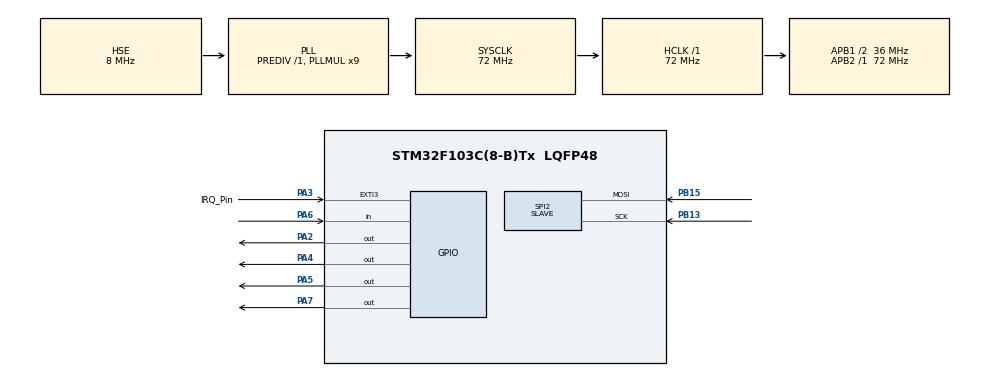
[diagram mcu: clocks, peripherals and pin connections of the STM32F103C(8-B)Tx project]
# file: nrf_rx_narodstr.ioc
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Dma.Request0=SPI2_RX
Dma.SPI2_RX.0.Direction=DMA_PERIPH_TO_MEMORY
Dma.SPI2_RX.0.Instance=DMA1_Channel4
Dma.SPI2_RX.0.MemDataAlignment=DMA_MDATAALIGN_HALFWORD
Dma.SPI2_RX.0.MemInc=DMA_MINC_DISABLE
Dma.SPI2_RX.0.Mode=DMA_CIRCULAR
Dma.SPI2_RX.0.PeriphDataAlignment=DMA_PDATAALIGN_HALFWORD
Dma.SPI2_RX.0.PeriphInc=DMA_PINC_DISABLE
Dma.SPI2_RX.0.Priority=DMA_PRIORITY_LOW
Mcu.Family=STM32F1
Mcu.Name=STM32F103C(8-B)Tx
Mcu.Package=LQFP48
NVIC.DMA1_Channel4_IRQn=true\:0\:0\:false\:false\:true\:false\:true\:true
NVIC.PriorityGroup=NVIC_PRIORITYGROUP_4
PA13.Mode=Serial_Wire
PA13.Signal=SYS_JTMS-SWDIO
PA14.Mode=Serial_Wire
PA14.Signal=SYS_JTCK-SWCLK
PA2.GPIO_Speed=GPIO_SPEED_FREQ_HIGH
PA2.Signal=GPIO_Output
PA3.GPIO_Label=IRQ_Pin
PA3.GPIO_ModeDefaultEXTI=GPIO_MODE_IT_RISING_FALLING
PA3.Signal=GPXTI3
PA4.GPIO_Speed=GPIO_SPEED_FREQ_HIGH
PA4.PinState=GPIO_PIN_SET
PA4.Signal=GPIO_Output
PA5.GPIO_Speed=GPIO_SPEED_FREQ_HIGH
PA5.Signal=GPIO_Output
PA6.Signal=GPIO_Input
PA7.GPIO_Speed=GPIO_SPEED_FREQ_HIGH
PA7.Signal=GPIO_Output
PB13.Mode=RX_Only_Simplex_Unidirect_Slave
PB13.Signal=SPI2_SCK
PB15.Mode=RX_Only_Simplex_Unidirect_Slave
PB15.Signal=SPI2_MOSI
PD0-OSC_IN.Mode=HSE-External-Oscillator
PD0-OSC_IN.Signal=RCC_OSC_IN
PD1-OSC_OUT.Mode=HSE-External-Oscillator
PD1-OSC_OUT.Signal=RCC_OSC_OUT
ProjectManager.HeapSize=0x200
ProjectManager.StackSize=0x400
ProjectManager.TargetToolchain=MDK-ARM V5.32
RCC.AHBFreq_Value=72000000
RCC.APB1CLKDivider=RCC_HCLK_DIV2
RCC.APB1Freq_Value=36000000
RCC.APB1TimFreq_Value=72000000
RCC.APB2Freq_Value=72000000
RCC.APB2TimFreq_Value=72000000
RCC.HCLKFreq_Value=72000000
RCC.PLLMUL=RCC_PLL_MUL9
RCC.PLLSourceVirtual=RCC_PLLSOURCE_HSE
RCC.SYSCLKFreq_VALUE=72000000
RCC.SYSCLKSource=RCC_SYSCLKSOURCE_PLLCLK
RCC.USBFreq_Value=72000000
SPI2.DataSize=SPI_DATASIZE_16BIT
SPI2.Direction=SPI_DIRECTION_2LINES_RXONLY
SPI2.Mode=SPI_MODE_SLAVE
SPI2.VirtualType=VM_SLAVE
TIM2.Prescaler=71
VP_TIM2_VS_ClockSourceINT.Mode=Internal
board=custom

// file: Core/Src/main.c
/* USER CODE BEGIN Header */
/**
  ******************************************************************************
  * @file           : main.c
  * @brief          : Main program body
  ******************************************************************************
  * @attention
  *
  * Copyright (c) 2024 STMicroelectronics.
  * All rights reserved.
  *
  * This software is licensed under terms that can be found in the LICENSE file
  * in the root directory of this software component.
  * If no LICENSE file comes with this software, it is provided AS-IS.
  *
  ******************************************************************************
  */
/* USER CODE END Header */
#include "main.h"
#include "dma.h"
#include "spi.h"
#include "tim.h"
#include "gpio.h"

/* USER CODE BEGIN Includes */
#include "NRF24.h"
/* USER CODE END Includes */

/* USER CODE BEGIN PV */
uint8_t res =0 ;
char str1[20]={0};
//uint8_t buf1[20]={0};

uint16_t tx_buf;

//uint8_t retr_cnt, dt;
//uint16_t i=1,retr_cnt_full;
uint16_t rxSpiDataAngle=0;
//uint8_t dt_reg=0;
/* USER CODE END PV */

void SystemClock_Config(void);

int main(void)
{

  /* MCU Configuration--------------------------------------------------------*/

  /* Reset of all peripherals, Initializes the Flash interface and the Systick. */
  HAL_Init();

  /* Configure the system clock */
  SystemClock_Config();

  /* Initialize all configured peripherals */
  MX_GPIO_Init();
  MX_DMA_Init();
  MX_TIM2_Init();
  MX_SPI2_Init();
  /* USER CODE BEGIN 2 */
	HAL_TIM_Base_Start(&htim2);
	HAL_Delay(200);

	NRF24_ini();

	HAL_Delay(1000);
  HAL_SPI_Receive_DMA(&hspi2, (uint8_t*) &rxSpiDataAngle, 1);
/*
  dt_reg = NRF24_ReadReg(CONFIG);

  dt_reg = NRF24_ReadReg(EN_AA);

  dt_reg = NRF24_ReadReg(EN_RXADDR);

  dt_reg = NRF24_ReadReg(STATUS);

  dt_reg = NRF24_ReadReg(RF_SETUP);

  NRF24_Read_Buf(TX_ADDR,buf1,3);

  NRF24_Read_Buf(RX_ADDR_P1,buf1,3);

  */

  /* USER CODE END 2 */

  /* Infinite loop */
  /* USER CODE BEGIN WHILE */
  while (1)
  {

		DelayMicro(1200);

	  NRF24L01_Send((uint8_t*)&rxSpiDataAngle);

 //   HAL_SPI_Receive(&hspi2, (uint8_t*)&rxSpiDataAngle, 1, 100);
    /* USER CODE END WHILE */

  }
}

void SystemClock_Config(void)
{
  RCC_OscInitTypeDef RCC_OscInitStruct = {0};
  RCC_ClkInitTypeDef RCC_ClkInitStruct = {0};

  /** Initializes the RCC Oscillators according to the specified parameters
  * in the RCC_OscInitTypeDef structure.
  */
  RCC_OscInitStruct.OscillatorType = RCC_OSCILLATORTYPE_HSE;
  RCC_OscInitStruct.HSEState = RCC_HSE_ON;
  RCC_OscInitStruct.HSEPredivValue = RCC_HSE_PREDIV_DIV1;
  RCC_OscInitStruct.HSIState = RCC_HSI_ON;
  RCC_OscInitStruct.PLL.PLLState = RCC_PLL_ON;
  RCC_OscInitStruct.PLL.PLLSource = RCC_PLLSOURCE_HSE;
  RCC_OscInitStruct.PLL.PLLMUL = RCC_PLL_MUL9;
  if (HAL_RCC_OscConfig(&RCC_OscInitStruct) != HAL_OK)
  {
    Error_Handler();
  }

  /** Initializes the CPU, AHB and APB buses clocks
  */
  RCC_ClkInitStruct.ClockType = RCC_CLOCKTYPE_HCLK|RCC_CLOCKTYPE_SYSCLK
                              |RCC_CLOCKTYPE_PCLK1|RCC_CLOCKTYPE_PCLK2;
  RCC_ClkInitStruct.SYSCLKSource = RCC_SYSCLKSOURCE_PLLCLK;
  RCC_ClkInitStruct.AHBCLKDivider = RCC_SYSCLK_DIV1;
  RCC_ClkInitStruct.APB1CLKDivider = RCC_HCLK_DIV2;
  RCC_ClkInitStruct.APB2CLKDivider = RCC_HCLK_DIV1;

  if (HAL_RCC_ClockConfig(&RCC_ClkInitStruct, FLASH_LATENCY_2) != HAL_OK)
  {
    Error_Handler();
  }
}

void Error_Handler(void)
{
  __disable_irq();
  while (1)
  {
  }
}
